# HDQ1W register map
Vendor: Texas Instruments
Peripheral module from a debugger description file (folder omap5430_ES2_PUBLIC).
Registers are 32-bit, read-only, reset 0x0 unless marked. A register's access mark holds for its fields unless they carry their own. Offsets are as the file gives them; lines under a group give offsets from that group; [hi:lo] are bit positions; {n}, {i} and the like mark numbered series; 'fields as' and 'values as' point back to an identical list; <NAME> marks a mode.

## HDQ1W
0x00 HDQ_REVISION reset not defined — This register contains the IP revision code
  [31:0] REVISION — IP revision
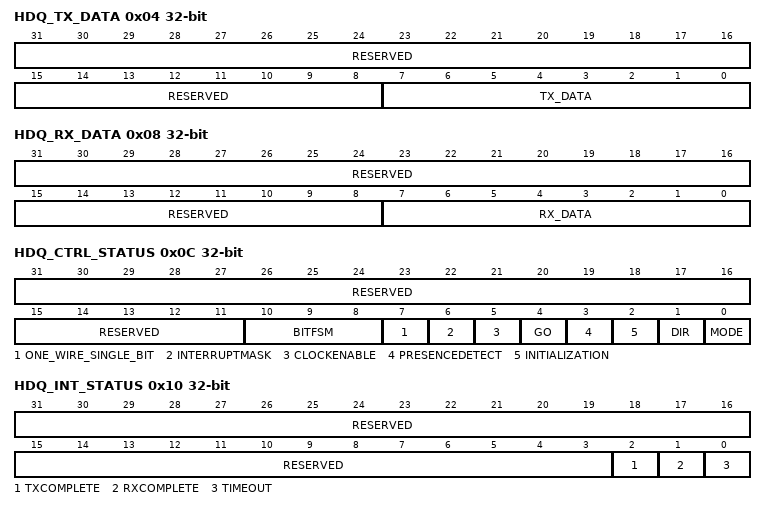
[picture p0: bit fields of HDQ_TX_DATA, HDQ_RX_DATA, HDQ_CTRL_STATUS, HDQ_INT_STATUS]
0x04 HDQ_TX_DATA access per field — This register contains the data to be transmitted.
  [31:8] RESERVED ro — Reads returns 0
  [7:0] TX_DATA rw — Transmit data (used in both HDQ and 1-Wire modes)
0x08 HDQ_RX_DATA — This register contains the data to be received.
  [31:8] RESERVED — Reads returns 0
  [7:0] RX_DATA — Receive data (used in both HDQ and 1-Wire modes)
0x0C HDQ_CTRL_STATUS access per field — This register provides status information about the module.
  [31:11] RESERVED rw — Reads returns 0
  [10:8] BITFSM rw — BITFSM delay value in 1.33 µs steps. 0x0 value corresponds to 1.33 µs.
  [7] ONE_WIRE_SINGLE_BIT rw — Single-bit mode for 1-Wire 0x0: Disabled 0x1: Enabled
  [6] INTERRUPTMASK rw — Interrupt masking bit 0x0: Interrupts disable 0x1: Interrupts enable
  [5] CLOCKENABLE rw — Power-down mode bit 0x0: Clock disable (power down) 0x1: Clock enable
  [4] GO rw — Go bit. Write 1 to start the appropriate operation. Bit returns to 0 after the operation is complete.
  [3] PRESENCEDETECT ro — Slave presence indicator. Actual only just after initialization time-out. Used in 1-Wire mode. Read-only flag. 0x0: No slave detected 0x1: Slave detected
  [2] INITIALIZATION rw — Write 1 to send initialization pulse. Bit returns to 0 after pulse is sent.
  [1] DIR rw — DIR bit, determines if next command is read or write 0x0: Write 0x1: Read
  [0] MODE rw — Mode selection bit 0x0: HDQ mode 0x1: 1-Wire mode
0x10 HDQ_INT_STATUS — This register controls interrupts status
  [31:3] RESERVED — Reads returns 0
  [2] TXCOMPLETE — TX-complete interrupt flag. Set to 1 if cause of interrupt. Set to 0 when register read.
  [1] RXCOMPLETE — Read-complete interrupt flag. Set to 1 if cause of interrupt. Set to 0 when register read.
  [0] TIMEOUT — Presence detect/timeout interrupt flag. In 1-Wire mode, set to 1 if slave's presence detected. In HDQ mode, set to 1 if timeout on read occurs. Set to 0 when register read.
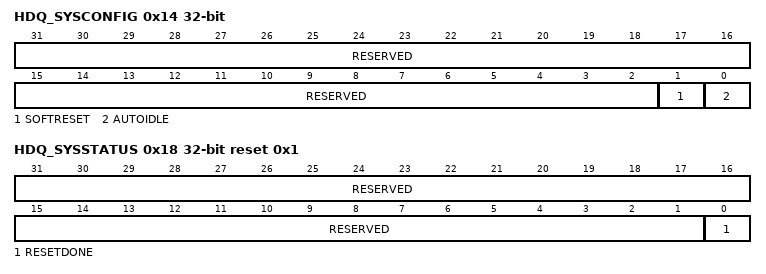
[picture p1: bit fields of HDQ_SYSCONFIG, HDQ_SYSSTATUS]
0x14 HDQ_SYSCONFIG rw — This register controls various bits
  [31:2] RESERVED — Reads returns 0
  [1] SOFTRESET — Start soft reset sequence. 0x0: Disabled 0x1: Enabled
  [0] AUTOIDLE — Interconnect idle. 0x0: Module clock is free-running. 0x1: Module is in power saving mode: Clock is running only when module is accessed or inside logic is in function to process events.
0x18 HDQ_SYSSTATUS reset 0x1 — This register monitors the reset sequence.
  [31:1] RESERVED — Reads returns 0
  [0] RESETDONE — Reset monitoring. 0x0: The module is currently performing its reset. When the module is in power-down mode, set to 0 to indicate this fact. 0x1: The module has finished its reset.
